VERSION ""

NS_ :

BS_:

BU_: TEST_NODE AREO_PRESSURE_SENS_B AREO_PRESSURE_SENS_A WHEEL_STRAIN_GAUGE_FR WHEEL_STRAIN_GAUGE_FL ACCU_FANS_DRIVER CAN_open_MASTER MAXON RES AREO_PRESSURE_SENS DV_BOARD RPI_LOGGER AREO_TEMP_SENS ANGLE_SENSOR BUZZER BRAKE_LIGHT MAIN SW LV_BMS Power_Module AMS_Master Pedals_frame GPS2CAN ADU FS_Datalogger
VAL_TABLE_ Rear_Sensor_Error 2 "OVER_RANGE" 1 "UNDER_RANGE" 0 "NO_ERROR" ;
VAL_TABLE_ Rear_CAN_Error 4 "CAN_FRAME_NOT_ACTUAL" 1 "NO_CAN_FRAME_READ" 0 "NO_ERROR" ;
VAL_TABLE_ Output_Error 2 "SET_ON_OVERCURRENT" 1 "OVERCURRENT" 0 "NO_ERROR" ;
VAL_TABLE_ BUZZER_REQUEST 2 "ASE" 1 "R2D" 0 "OFF" ;
VAL_TABLE_ Imd_Status_t 9 "IMD_STATE_UNKNOWN" 8 "IMD_STATE_INVALID_50HZ" 7 "IMD_STATE_KI31_FAULT_50HZ" 6 "IMD_STATE_INVALID_40HZ" 5 "IMD_STATE_DEVICE_ERROR_40HZ" 4 "IMD_STATE_INVALID_30HZ" 3 "IMD_STATE_SST_BAD_30HZ" 2 "IMD_STATE_SST_GOOD_30HZ" 1 "IMD_STATE_UNDERVOLT_20HZ" 0 "IMD_STATE_NORMAL_10HZ" ;
VAL_TABLE_ Main_State_t 5 "Error" 4 "TS_Shutdown" 3 "ReadyToDrive" 2 "TS_Active" 1 "Standby" 0 "Init" ;
VAL_TABLE_ SWAngleSensorTypeTable 5 "SENS_TLE5009_FIR" 4 "TLE5009_AVRG" 3 "MA734" 2 "MA730" 1 "AS5600" 0 "TLE5009" ;
VAL_TABLE_ BMS_State_t 9 "BMS_TIMEOUT" 8 "BMS_CELLS_BALANCING" 7 "BMS_BALANCING_TRANS" 6 "BMS_TSACTIVE_TRANS" 5 "BMS_ERROR" 4 "BMS_BP_BALANCING" 3 "BMS_TSACTIVE" 2 "BMS_PRECHARGE" 1 "BMS_TSOFF" 0 "BMS_INIT" ;
VAL_TABLE_ Service_brake_state_enum 3 "Service_brake_state_available" 2 "Service_brake_state_engaged" 1 "Service_brake_state_disengaged" ;
VAL_TABLE_ AMI_state_enum 6 "AMI_state_autocross" 5 "AMI_state_inspection" 4 "AMI_state_braketest" 3 "AMI_state_trackdrive" 2 "AMI_state_skidpad" 1 "AMI_state_acceleration" ;
VAL_TABLE_ EBS_state_enum 3 "EBS_state_activated" 2 "EBS_state_armed" 1 "EBS_state_unavailable" ;
VAL_TABLE_ AS_state_enum 5 "AS_state_finish" 4 "AS_state_emergency_brake" 3 "AS_state_driving " 2 "AS_state_ready" 1 "AS_state_off" ;

BO_ 3221225472 VECTOR__INDEPENDENT_SIG_MSG: 0 Vector__XXX
 SG_ AngleRLError : 0|8@0+ (1,0) [0|255] "" Vector__XXX
 SG_ AngleRL : 0|32@0- (1E-06,0) [-2147.483648|2147.483647] "deg" Vector__XXX
 SG_ AngleRRError : 0|8@0+ (1,0) [0|255] "" Vector__XXX
 SG_ AngleRR : 0|32@0- (1E-06,0) [-2147.483648|2147.483647] "deg" Vector__XXX
 SG_ AngleFLError : 0|8@0+ (1,0) [0|255] "" Vector__XXX
 SG_ AngleFL : 0|32@0- (1E-06,0) [-2147.483648|2147.483647] "deg" Vector__XXX
 SG_ AngleFRError : 0|8@0+ (1,0) [0|255] "" Vector__XXX
 SG_ AngleFR : 0|32@0- (1E-06,0) [-2147.483648|2147.483647] "deg" Vector__XXX
 SG_ AngleError : 0|8@0+ (1,0) [0|255] "" Vector__XXX
 SG_ Angle : 0|32@0- (1E-06,0) [-2147.483648|2147.483647] "deg" Vector__XXX
 SG_ AMKError : 0|8@0+ (1,0) [0|255] "" Vector__XXX
 SG_ AMS : 0|1@0+ (1,0) [0|255] "" Vector__XXX
 SG_ Buzzer : 0|8@0+ (1,0) [0|255] "" Vector__XXX

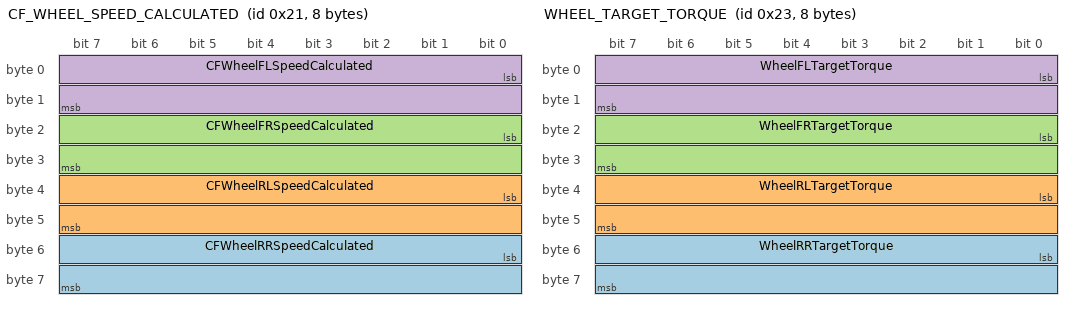
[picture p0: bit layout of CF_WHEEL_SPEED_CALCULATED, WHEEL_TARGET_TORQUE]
BO_ 33 CF_WHEEL_SPEED_CALCULATED: 8 MAIN
 SG_ CFWheelRRSpeedCalculated : 48|16@1- (1,0) [-32768|32767] "rpm"  RPI_LOGGER
 SG_ CFWheelRLSpeedCalculated : 32|16@1- (1,0) [-32768|32767] "rpm"  RPI_LOGGER
 SG_ CFWheelFRSpeedCalculated : 16|16@1- (1,0) [-32768|32767] "rpm"  RPI_LOGGER
 SG_ CFWheelFLSpeedCalculated : 0|16@1- (1,0) [-32768|32767] "rpm"  RPI_LOGGER

BO_ 35 WHEEL_TARGET_TORQUE: 8 MAIN
 SG_ WheelRRTargetTorque : 48|16@1- (1,0) [-32768|32767] "0.1% Mn"  RPI_LOGGER
 SG_ WheelRLTargetTorque : 32|16@1- (1,0) [-32768|32767] "0.1% Mn"  RPI_LOGGER
 SG_ WheelFRTargetTorque : 16|16@1- (1,0) [-32768|32767] "0.1% Mn"  RPI_LOGGER
 SG_ WheelFLTargetTorque : 0|16@1- (1,0) [-32768|32767] "0.1% Mn"  RPI_LOGGER

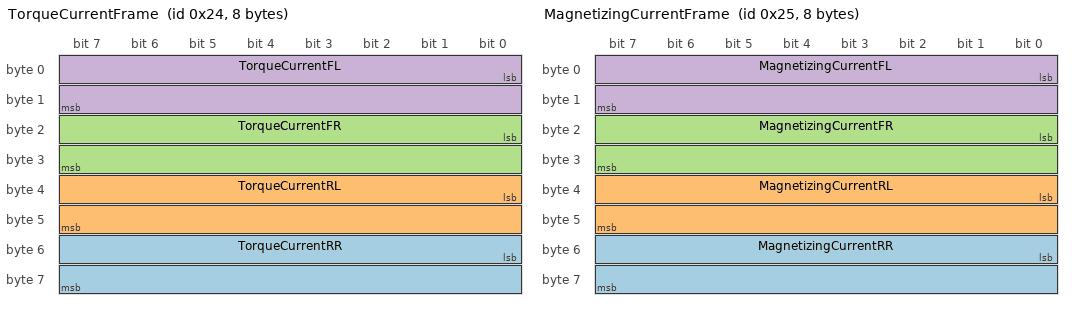
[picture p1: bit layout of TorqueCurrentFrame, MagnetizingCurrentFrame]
BO_ 36 TorqueCurrentFrame: 8 MAIN
 SG_ TorqueCurrentRR : 48|16@1- (1,0) [-32768|32767] "A"  RPI_LOGGER
 SG_ TorqueCurrentRL : 32|16@1- (1,0) [-32768|32767] "A"  RPI_LOGGER
 SG_ TorqueCurrentFR : 16|16@1- (1,0) [-32768|32767] "A"  RPI_LOGGER
 SG_ TorqueCurrentFL : 0|16@1- (1,0) [-32768|32767] "A"  RPI_LOGGER

BO_ 37 MagnetizingCurrentFrame: 8 MAIN
 SG_ MagnetizingCurrentRR : 48|16@1- (1,0) [-32768|32767] "A"  RPI_LOGGER
 SG_ MagnetizingCurrentRL : 32|16@1- (1,0) [-32768|32767] "A"  RPI_LOGGER
 SG_ MagnetizingCurrentFR : 16|16@1- (1,0) [-32768|32767] "A"  RPI_LOGGER
 SG_ MagnetizingCurrentFL : 0|16@1- (1,0) [-32768|32767] "A"  RPI_LOGGER

BO_ 1315 AMS_IMD_SDC_FRAME_DEBUG: 6 AMS_Master
 SG_ AMS_SDC_Volt_Debug : 24|16@1+ (0.001,0) [0|65.535] "V"  RPI_LOGGER
 SG_ ImdResistance : 8|16@1+ (1,0) [0|65535] "kOhm"  RPI_LOGGER
 SG_ ImdStatus : 0|8@1+ (1,0) [0|255] ""  RPI_LOGGER

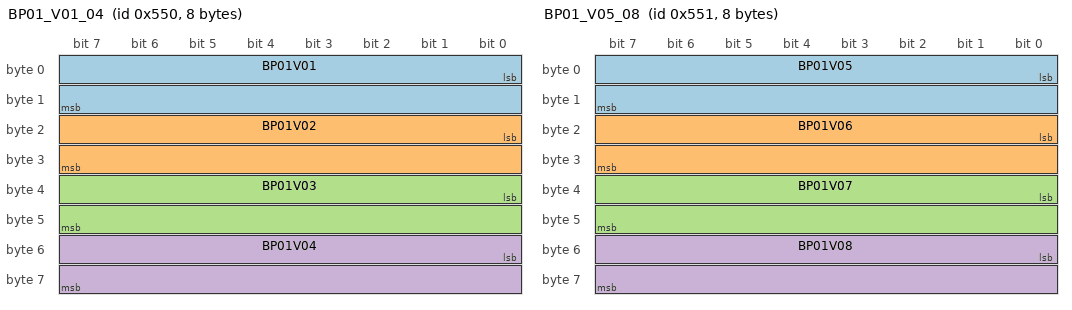
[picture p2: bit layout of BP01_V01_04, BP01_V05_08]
BO_ 1360 BP01_V01_04: 8 AMS_Master
 SG_ BP01V01 : 0|16@1+ (1,0) [0|65535] "mV"  RPI_LOGGER
 SG_ BP01V02 : 16|16@1+ (1,0) [0|65535] "mV"  RPI_LOGGER
 SG_ BP01V03 : 32|16@1+ (1,0) [0|65535] "mV"  RPI_LOGGER
 SG_ BP01V04 : 48|16@1+ (1,0) [0|65535] "mV"  RPI_LOGGER

BO_ 1361 BP01_V05_08: 8 AMS_Master
 SG_ BP01V05 : 0|16@1+ (1,0) [0|65535] "mV"  RPI_LOGGER
 SG_ BP01V06 : 16|16@1+ (1,0) [0|65535] "mV"  RPI_LOGGER
 SG_ BP01V07 : 32|16@1+ (1,0) [0|65535] "mV"  RPI_LOGGER
 SG_ BP01V08 : 48|16@1+ (1,0) [0|65535] "mV"  RPI_LOGGER

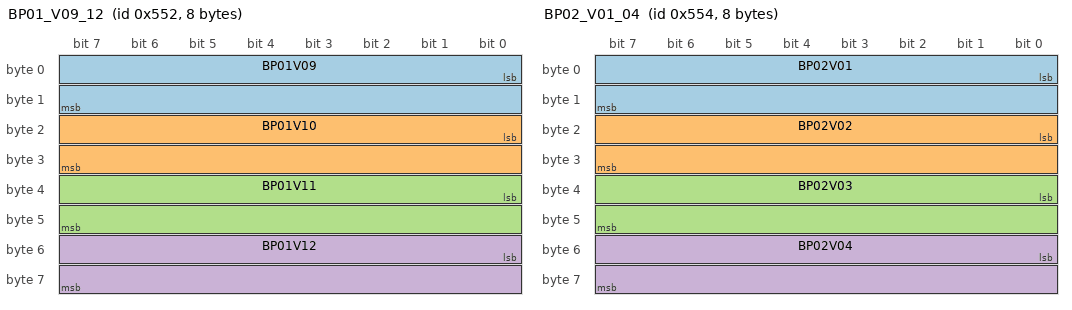
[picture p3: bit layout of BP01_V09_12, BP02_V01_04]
BO_ 1362 BP01_V09_12: 8 AMS_Master
 SG_ BP01V09 : 0|16@1+ (1,0) [0|65535] "mV"  RPI_LOGGER
 SG_ BP01V10 : 16|16@1+ (1,0) [0|65535] "mV"  RPI_LOGGER
 SG_ BP01V11 : 32|16@1+ (1,0) [0|65535] "mV"  RPI_LOGGER
 SG_ BP01V12 : 48|16@1+ (1,0) [0|65535] "mV"  RPI_LOGGER

BO_ 1363 BP01_V13_14: 8 AMS_Master
 SG_ BP01V13 : 0|16@1+ (1,0) [0|65535] "mV"  RPI_LOGGER
 SG_ BP01V14 : 16|16@1+ (1,0) [0|65535] "mV"  RPI_LOGGER

BO_ 1364 BP02_V01_04: 8 AMS_Master
 SG_ BP02V01 : 0|16@1+ (1,0) [0|65535] "mV"  RPI_LOGGER
 SG_ BP02V02 : 16|16@1+ (1,0) [0|65535] "mV"  RPI_LOGGER
 SG_ BP02V03 : 32|16@1+ (1,0) [0|65535] "mV"  RPI_LOGGER
 SG_ BP02V04 : 48|16@1+ (1,0) [0|65535] "mV"  RPI_LOGGER

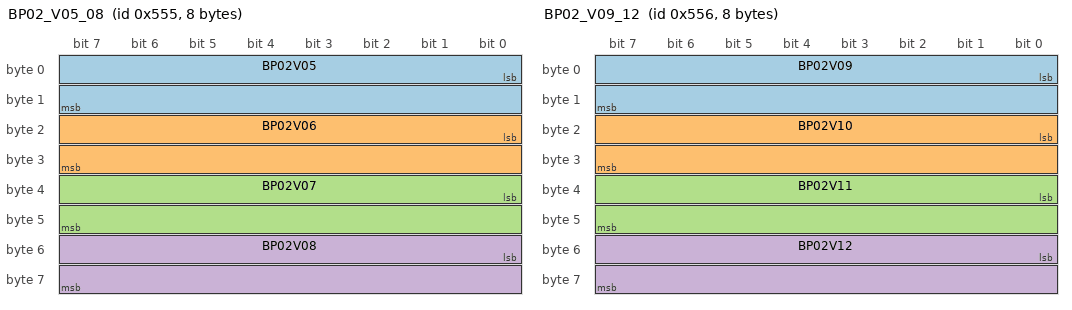
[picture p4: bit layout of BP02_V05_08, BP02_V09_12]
BO_ 1365 BP02_V05_08: 8 AMS_Master
 SG_ BP02V05 : 0|16@1+ (1,0) [0|65535] "mV"  RPI_LOGGER
 SG_ BP02V06 : 16|16@1+ (1,0) [0|65535] "mV"  RPI_LOGGER
 SG_ BP02V07 : 32|16@1+ (1,0) [0|65535] "mV"  RPI_LOGGER
 SG_ BP02V08 : 48|16@1+ (1,0) [0|65535] "mV"  RPI_LOGGER

BO_ 1366 BP02_V09_12: 8 AMS_Master
 SG_ BP02V09 : 0|16@1+ (1,0) [0|65535] "mV"  RPI_LOGGER
 SG_ BP02V10 : 16|16@1+ (1,0) [0|65535] "mV"  RPI_LOGGER
 SG_ BP02V11 : 32|16@1+ (1,0) [0|65535] "mV"  RPI_LOGGER
 SG_ BP02V12 : 48|16@1+ (1,0) [0|65535] "mV"  RPI_LOGGER

BO_ 1367 BP02_V13_14: 8 AMS_Master
 SG_ BP02V13 : 0|16@1+ (1,0) [0|65535] "mV"  RPI_LOGGER
 SG_ BP02V14 : 16|16@1+ (1,0) [0|65535] "mV"  RPI_LOGGER

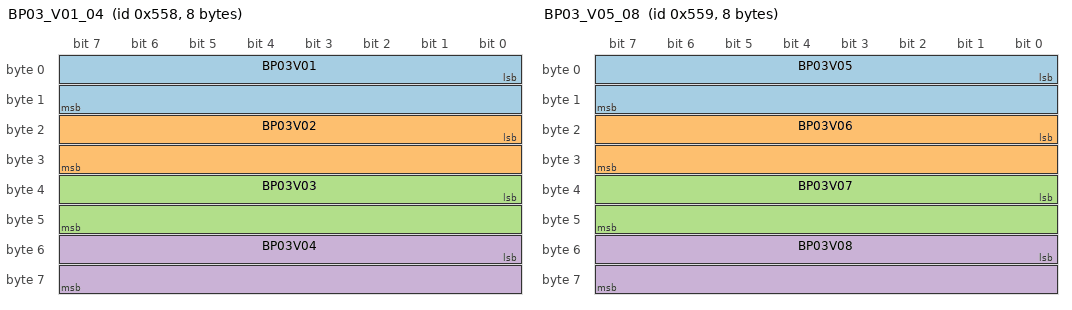
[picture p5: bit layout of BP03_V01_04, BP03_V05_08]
BO_ 1368 BP03_V01_04: 8 AMS_Master
 SG_ BP03V01 : 0|16@1+ (1,0) [0|65535] "mV"  RPI_LOGGER
 SG_ BP03V02 : 16|16@1+ (1,0) [0|65535] "mV"  RPI_LOGGER
 SG_ BP03V03 : 32|16@1+ (1,0) [0|65535] "mV"  RPI_LOGGER
 SG_ BP03V04 : 48|16@1+ (1,0) [0|65535] "mV"  RPI_LOGGER

BO_ 1369 BP03_V05_08: 8 AMS_Master
 SG_ BP03V05 : 0|16@1+ (1,0) [0|65535] "mV"  RPI_LOGGER
 SG_ BP03V06 : 16|16@1+ (1,0) [0|65535] "mV"  RPI_LOGGER
 SG_ BP03V07 : 32|16@1+ (1,0) [0|65535] "mV"  RPI_LOGGER
 SG_ BP03V08 : 48|16@1+ (1,0) [0|65535] "mV"  RPI_LOGGER

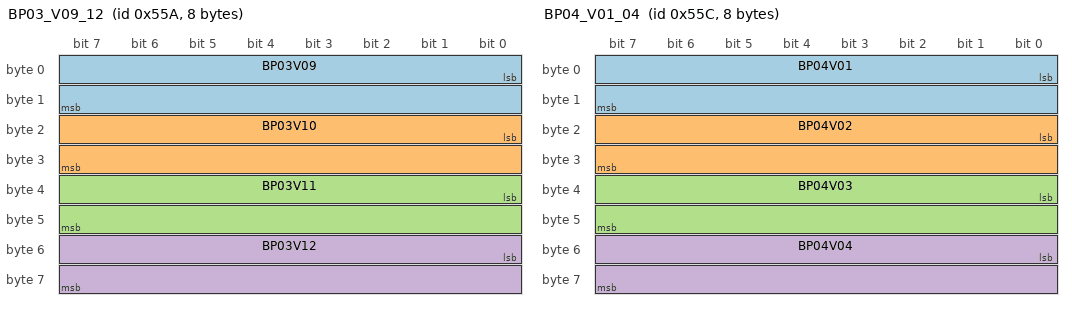
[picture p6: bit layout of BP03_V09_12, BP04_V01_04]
BO_ 1370 BP03_V09_12: 8 AMS_Master
 SG_ BP03V09 : 0|16@1+ (1,0) [0|65535] "mV"  RPI_LOGGER
 SG_ BP03V10 : 16|16@1+ (1,0) [0|65535] "mV"  RPI_LOGGER
 SG_ BP03V11 : 32|16@1+ (1,0) [0|65535] "mV"  RPI_LOGGER
 SG_ BP03V12 : 48|16@1+ (1,0) [0|65535] "mV"  RPI_LOGGER

BO_ 1371 BP03_V13_14: 8 AMS_Master
 SG_ BP03V13 : 0|16@1+ (1,0) [0|65535] "mV"  RPI_LOGGER
 SG_ BP03V14 : 16|16@1+ (1,0) [0|65535] "mV"  RPI_LOGGER

BO_ 1372 BP04_V01_04: 8 AMS_Master
 SG_ BP04V01 : 0|16@1+ (1,0) [0|65535] "mV"  RPI_LOGGER
 SG_ BP04V02 : 16|16@1+ (1,0) [0|65535] "mV"  RPI_LOGGER
 SG_ BP04V03 : 32|16@1+ (1,0) [0|65535] "mV"  RPI_LOGGER
 SG_ BP04V04 : 48|16@1+ (1,0) [0|65535] "mV"  RPI_LOGGER

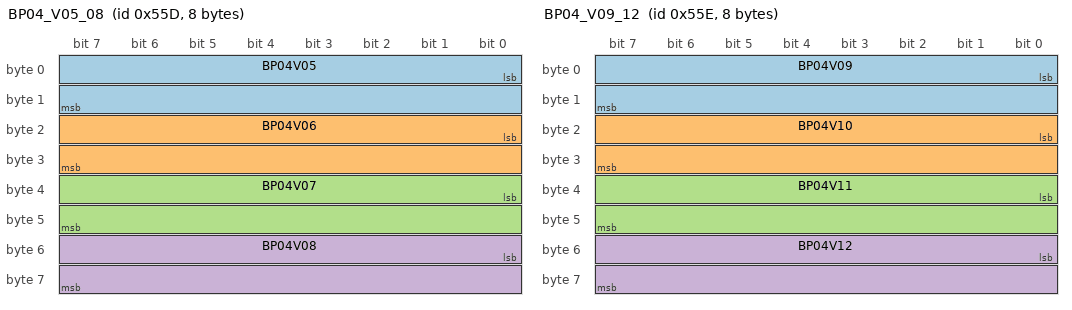
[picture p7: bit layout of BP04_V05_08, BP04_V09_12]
BO_ 1373 BP04_V05_08: 8 AMS_Master
 SG_ BP04V05 : 0|16@1+ (1,0) [0|65535] "mV"  RPI_LOGGER
 SG_ BP04V06 : 16|16@1+ (1,0) [0|65535] "mV"  RPI_LOGGER
 SG_ BP04V07 : 32|16@1+ (1,0) [0|65535] "mV"  RPI_LOGGER
 SG_ BP04V08 : 48|16@1+ (1,0) [0|65535] "mV"  RPI_LOGGER

BO_ 1374 BP04_V09_12: 8 AMS_Master
 SG_ BP04V09 : 0|16@1+ (1,0) [0|65535] "mV"  RPI_LOGGER
 SG_ BP04V10 : 16|16@1+ (1,0) [0|65535] "mV"  RPI_LOGGER
 SG_ BP04V11 : 32|16@1+ (1,0) [0|65535] "mV"  RPI_LOGGER
 SG_ BP04V12 : 48|16@1+ (1,0) [0|65535] "mV"  RPI_LOGGER

BO_ 1375 BP04_V13_14: 8 AMS_Master
 SG_ BP04V13 : 0|16@1+ (1,0) [0|65535] "mV"  RPI_LOGGER
 SG_ BP04V14 : 16|16@1+ (1,0) [0|65535] "mV"  RPI_LOGGER

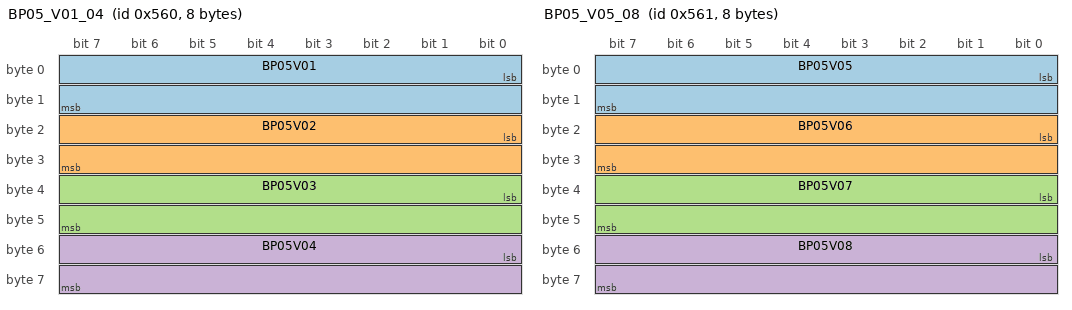
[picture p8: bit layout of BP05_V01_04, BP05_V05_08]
BO_ 1376 BP05_V01_04: 8 AMS_Master
 SG_ BP05V01 : 0|16@1+ (1,0) [0|65535] "mV"  RPI_LOGGER
 SG_ BP05V02 : 16|16@1+ (1,0) [0|65535] "mV"  RPI_LOGGER
 SG_ BP05V03 : 32|16@1+ (1,0) [0|65535] "mV"  RPI_LOGGER
 SG_ BP05V04 : 48|16@1+ (1,0) [0|65535] "mV"  RPI_LOGGER

BO_ 1377 BP05_V05_08: 8 AMS_Master
 SG_ BP05V05 : 0|16@1+ (1,0) [0|65535] "mV"  RPI_LOGGER
 SG_ BP05V06 : 16|16@1+ (1,0) [0|65535] "mV"  RPI_LOGGER
 SG_ BP05V07 : 32|16@1+ (1,0) [0|65535] "mV"  RPI_LOGGER
 SG_ BP05V08 : 48|16@1+ (1,0) [0|65535] "mV"  RPI_LOGGER

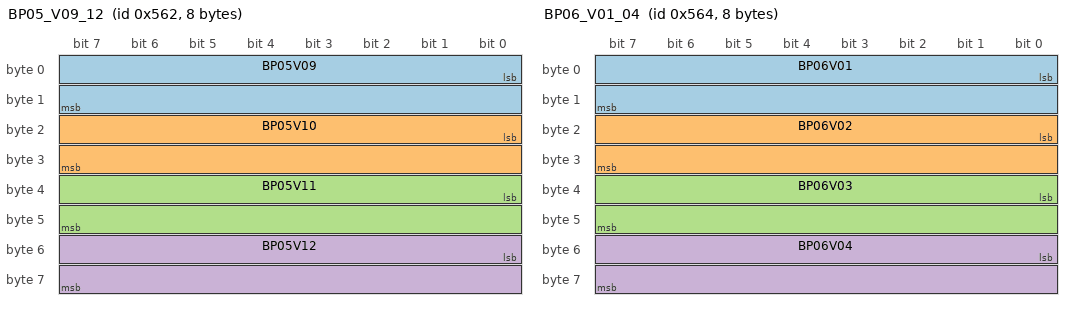
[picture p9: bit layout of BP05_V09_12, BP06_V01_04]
BO_ 1378 BP05_V09_12: 8 AMS_Master
 SG_ BP05V09 : 0|16@1+ (1,0) [0|65535] "mV"  RPI_LOGGER
 SG_ BP05V10 : 16|16@1+ (1,0) [0|65535] "mV"  RPI_LOGGER
 SG_ BP05V11 : 32|16@1+ (1,0) [0|65535] "mV"  RPI_LOGGER
 SG_ BP05V12 : 48|16@1+ (1,0) [0|65535] "mV"  RPI_LOGGER

BO_ 1379 BP05_V13_14: 8 AMS_Master
 SG_ BP05V13 : 0|16@1+ (1,0) [0|65535] "mV"  RPI_LOGGER
 SG_ BP05V14 : 16|16@1+ (1,0) [0|65535] "mV"  RPI_LOGGER

BO_ 1380 BP06_V01_04: 8 AMS_Master
 SG_ BP06V01 : 0|16@1+ (1,0) [0|65535] "mV"  RPI_LOGGER
 SG_ BP06V02 : 16|16@1+ (1,0) [0|65535] "mV"  RPI_LOGGER
 SG_ BP06V03 : 32|16@1+ (1,0) [0|65535] "mV"  RPI_LOGGER
 SG_ BP06V04 : 48|16@1+ (1,0) [0|65535] "mV"  RPI_LOGGER

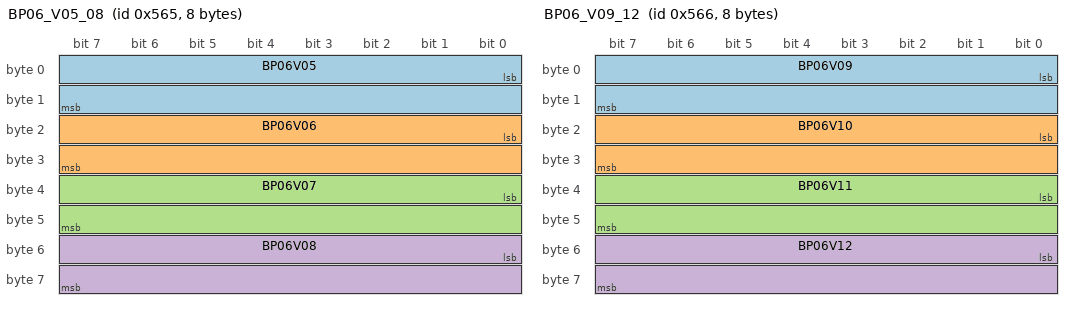
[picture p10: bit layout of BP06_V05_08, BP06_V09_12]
BO_ 1381 BP06_V05_08: 8 AMS_Master
 SG_ BP06V05 : 0|16@1+ (1,0) [0|65535] "mV"  RPI_LOGGER
 SG_ BP06V06 : 16|16@1+ (1,0) [0|65535] "mV"  RPI_LOGGER
 SG_ BP06V07 : 32|16@1+ (1,0) [0|65535] "mV"  RPI_LOGGER
 SG_ BP06V08 : 48|16@1+ (1,0) [0|65535] "mV"  RPI_LOGGER

BO_ 1382 BP06_V09_12: 8 AMS_Master
 SG_ BP06V09 : 0|16@1+ (1,0) [0|65535] "mV"  RPI_LOGGER
 SG_ BP06V10 : 16|16@1+ (1,0) [0|65535] "mV"  RPI_LOGGER
 SG_ BP06V11 : 32|16@1+ (1,0) [0|65535] "mV"  RPI_LOGGER
 SG_ BP06V12 : 48|16@1+ (1,0) [0|65535] "mV"  RPI_LOGGER

BO_ 1383 BP06_V13_14: 8 AMS_Master
 SG_ BP06V13 : 0|16@1+ (1,0) [0|65535] "mV"  RPI_LOGGER
 SG_ BP06V14 : 16|16@1+ (1,0) [0|65535] "mV"  RPI_LOGGER

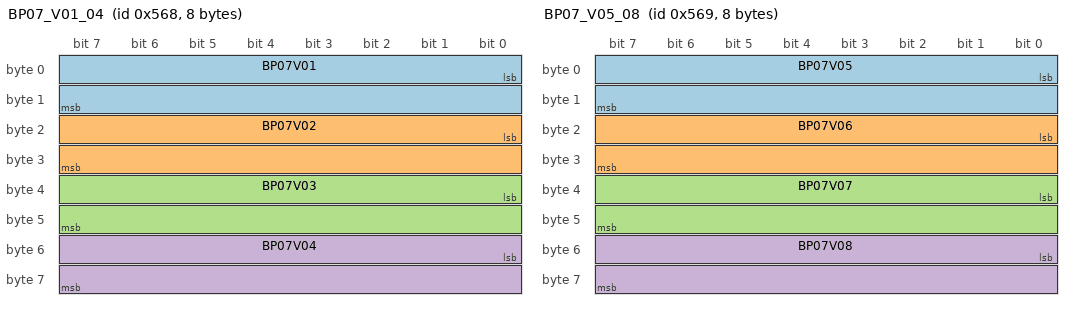
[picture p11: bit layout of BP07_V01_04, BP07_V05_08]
BO_ 1384 BP07_V01_04: 8 AMS_Master
 SG_ BP07V01 : 0|16@1+ (1,0) [0|65535] "mV"  RPI_LOGGER
 SG_ BP07V02 : 16|16@1+ (1,0) [0|65535] "mV"  RPI_LOGGER
 SG_ BP07V03 : 32|16@1+ (1,0) [0|65535] "mV"  RPI_LOGGER
 SG_ BP07V04 : 48|16@1+ (1,0) [0|65535] "mV"  RPI_LOGGER

BO_ 1385 BP07_V05_08: 8 AMS_Master
 SG_ BP07V05 : 0|16@1+ (1,0) [0|65535] "mV"  RPI_LOGGER
 SG_ BP07V06 : 16|16@1+ (1,0) [0|65535] "mV"  RPI_LOGGER
 SG_ BP07V07 : 32|16@1+ (1,0) [0|65535] "mV"  RPI_LOGGER
 SG_ BP07V08 : 48|16@1+ (1,0) [0|65535] "mV"  RPI_LOGGER

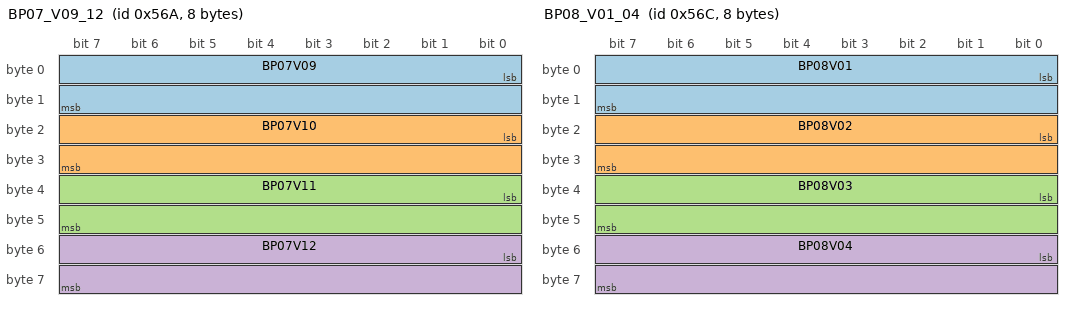
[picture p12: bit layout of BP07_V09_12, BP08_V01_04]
BO_ 1386 BP07_V09_12: 8 AMS_Master
 SG_ BP07V09 : 0|16@1+ (1,0) [0|65535] "mV"  RPI_LOGGER
 SG_ BP07V10 : 16|16@1+ (1,0) [0|65535] "mV"  RPI_LOGGER
 SG_ BP07V11 : 32|16@1+ (1,0) [0|65535] "mV"  RPI_LOGGER
 SG_ BP07V12 : 48|16@1+ (1,0) [0|65535] "mV"  RPI_LOGGER

BO_ 1387 BP07_V13_14: 8 AMS_Master
 SG_ BP07V13 : 0|16@1+ (1,0) [0|65535] "mV"  RPI_LOGGER
 SG_ BP07V14 : 16|16@1+ (1,0) [0|65535] "mV"  RPI_LOGGER

BO_ 1388 BP08_V01_04: 8 AMS_Master
 SG_ BP08V01 : 0|16@1+ (1,0) [0|65535] "mV"  RPI_LOGGER
 SG_ BP08V02 : 16|16@1+ (1,0) [0|65535] "mV"  RPI_LOGGER
 SG_ BP08V03 : 32|16@1+ (1,0) [0|65535] "mV"  RPI_LOGGER
 SG_ BP08V04 : 48|16@1+ (1,0) [0|65535] "mV"  RPI_LOGGER

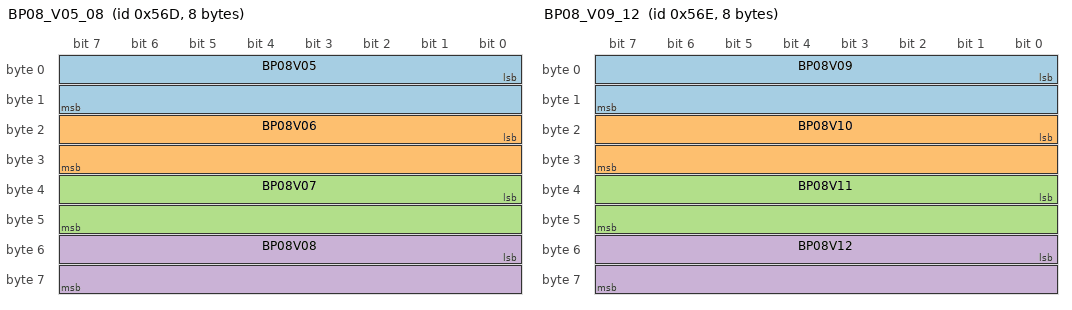
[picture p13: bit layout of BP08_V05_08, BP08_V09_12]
BO_ 1389 BP08_V05_08: 8 AMS_Master
 SG_ BP08V05 : 0|16@1+ (1,0) [0|65535] "mV"  RPI_LOGGER
 SG_ BP08V06 : 16|16@1+ (1,0) [0|65535] "mV"  RPI_LOGGER
 SG_ BP08V07 : 32|16@1+ (1,0) [0|65535] "mV"  RPI_LOGGER
 SG_ BP08V08 : 48|16@1+ (1,0) [0|65535] "mV"  RPI_LOGGER

BO_ 1390 BP08_V09_12: 8 AMS_Master
 SG_ BP08V09 : 0|16@1+ (1,0) [0|65535] "mV"  RPI_LOGGER
 SG_ BP08V10 : 16|16@1+ (1,0) [0|65535] "mV"  RPI_LOGGER
 SG_ BP08V11 : 32|16@1+ (1,0) [0|65535] "mV"  RPI_LOGGER
 SG_ BP08V12 : 48|16@1+ (1,0) [0|65535] "mV"  RPI_LOGGER

BO_ 1391 BP08_V13_14: 8 AMS_Master
 SG_ BP08V13 : 0|16@1+ (1,0) [0|65535] "mV"  RPI_LOGGER
 SG_ BP08V14 : 16|16@1+ (1,0) [0|65535] "mV"  RPI_LOGGER

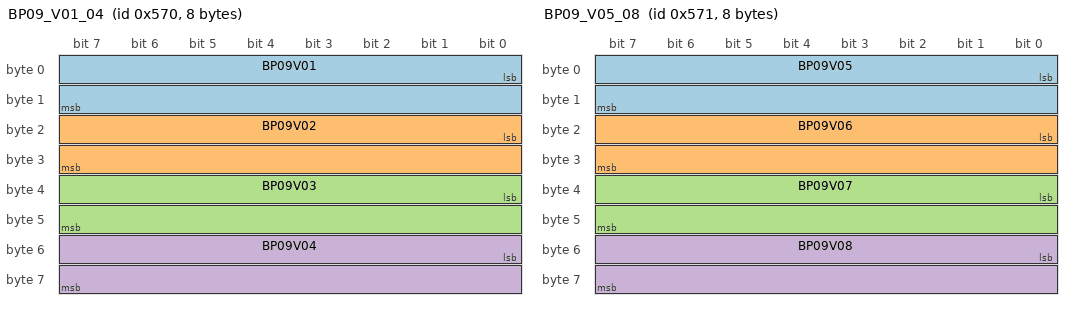
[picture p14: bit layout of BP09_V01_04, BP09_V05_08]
BO_ 1392 BP09_V01_04: 8 AMS_Master
 SG_ BP09V01 : 0|16@1+ (1,0) [0|65535] "mV"  RPI_LOGGER
 SG_ BP09V02 : 16|16@1+ (1,0) [0|65535] "mV"  RPI_LOGGER
 SG_ BP09V03 : 32|16@1+ (1,0) [0|65535] "mV"  RPI_LOGGER
 SG_ BP09V04 : 48|16@1+ (1,0) [0|65535] "mV"  RPI_LOGGER

BO_ 1393 BP09_V05_08: 8 AMS_Master
 SG_ BP09V05 : 0|16@1+ (1,0) [0|65535] "mV"  RPI_LOGGER
 SG_ BP09V06 : 16|16@1+ (1,0) [0|65535] "mV"  RPI_LOGGER
 SG_ BP09V07 : 32|16@1+ (1,0) [0|65535] "mV"  RPI_LOGGER
 SG_ BP09V08 : 48|16@1+ (1,0) [0|65535] "mV"  RPI_LOGGER

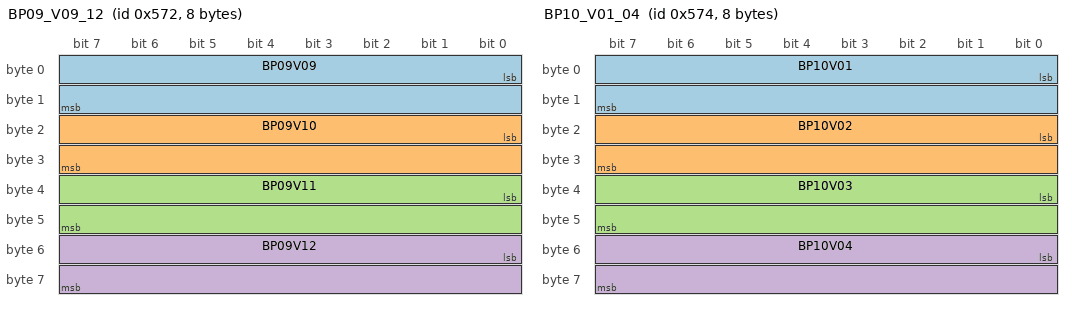
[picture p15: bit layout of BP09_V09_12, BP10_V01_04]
BO_ 1394 BP09_V09_12: 8 AMS_Master
 SG_ BP09V09 : 0|16@1+ (1,0) [0|65535] "mV"  RPI_LOGGER
 SG_ BP09V10 : 16|16@1+ (1,0) [0|65535] "mV"  RPI_LOGGER
 SG_ BP09V11 : 32|16@1+ (1,0) [0|65535] "mV"  RPI_LOGGER
 SG_ BP09V12 : 48|16@1+ (1,0) [0|65535] "mV"  RPI_LOGGER

BO_ 1395 BP09_V13_14: 8 AMS_Master
 SG_ BP09V13 : 0|16@1+ (1,0) [0|65535] "mV"  RPI_LOGGER
 SG_ BP09V14 : 16|16@1+ (1,0) [0|65535] "mV"  RPI_LOGGER

BO_ 1396 BP10_V01_04: 8 AMS_Master
 SG_ BP10V01 : 0|16@1+ (1,0) [0|65535] "mV"  RPI_LOGGER
 SG_ BP10V02 : 16|16@1+ (1,0) [0|65535] "mV"  RPI_LOGGER
 SG_ BP10V03 : 32|16@1+ (1,0) [0|65535] "mV"  RPI_LOGGER
 SG_ BP10V04 : 48|16@1+ (1,0) [0|65535] "mV"  RPI_LOGGER

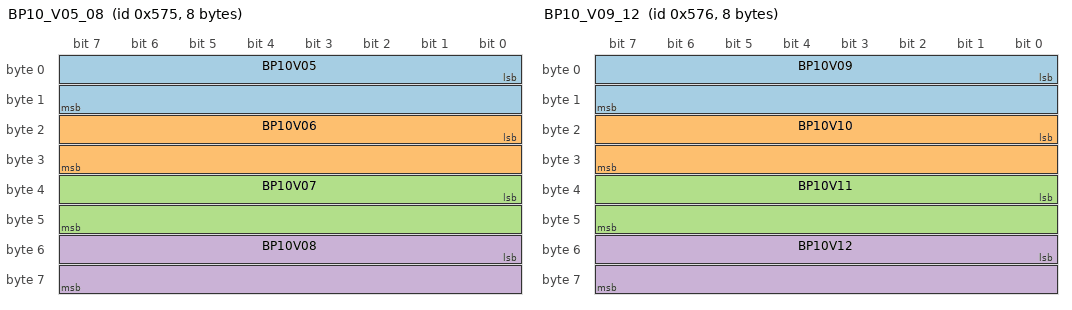
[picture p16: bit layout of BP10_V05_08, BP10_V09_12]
BO_ 1397 BP10_V05_08: 8 AMS_Master
 SG_ BP10V05 : 0|16@1+ (1,0) [0|65535] "mV"  RPI_LOGGER
 SG_ BP10V06 : 16|16@1+ (1,0) [0|65535] "mV"  RPI_LOGGER
 SG_ BP10V07 : 32|16@1+ (1,0) [0|65535] "mV"  RPI_LOGGER
 SG_ BP10V08 : 48|16@1+ (1,0) [0|65535] "mV"  RPI_LOGGER

BO_ 1398 BP10_V09_12: 8 AMS_Master
 SG_ BP10V09 : 0|16@1+ (1,0) [0|65535] "mV"  RPI_LOGGER
 SG_ BP10V10 : 16|16@1+ (1,0) [0|65535] "mV"  RPI_LOGGER
 SG_ BP10V11 : 32|16@1+ (1,0) [0|65535] "mV"  RPI_LOGGER
 SG_ BP10V12 : 48|16@1+ (1,0) [0|65535] "mV"  RPI_LOGGER

BO_ 1399 BP10_V13_14: 8 AMS_Master
 SG_ BP10V13 : 0|16@1+ (1,0) [0|65535] "mV"  RPI_LOGGER
 SG_ BP10V14 : 16|16@1+ (1,0) [0|65535] "mV"  RPI_LOGGER

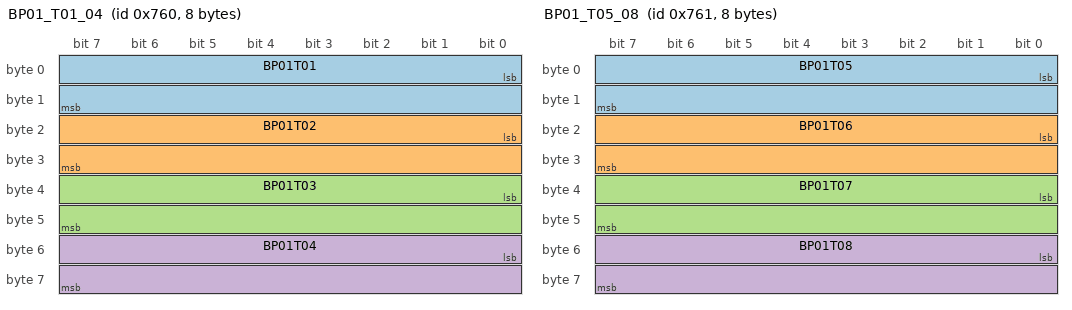
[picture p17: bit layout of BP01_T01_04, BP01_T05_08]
BO_ 1888 BP01_T01_04: 8 AMS_Master
 SG_ BP01T01 : 0|16@1+ (0.1,0) [0|6553.5] "C"  RPI_LOGGER
 SG_ BP01T02 : 16|16@1+ (0.1,0) [0|6553.5] "C"  RPI_LOGGER
 SG_ BP01T03 : 32|16@1+ (0.1,0) [0|6553.5] "C"  RPI_LOGGER
 SG_ BP01T04 : 48|16@1+ (0.1,0) [0|6553.5] "C"  RPI_LOGGER

BO_ 1889 BP01_T05_08: 8 AMS_Master
 SG_ BP01T05 : 0|16@1+ (0.1,0) [0|6553.5] "C"  RPI_LOGGER
 SG_ BP01T06 : 16|16@1+ (0.1,0) [0|6553.5] "C"  RPI_LOGGER
 SG_ BP01T07 : 32|16@1+ (0.1,0) [0|6553.5] "C"  RPI_LOGGER
 SG_ BP01T08 : 48|16@1+ (0.1,0) [0|6553.5] "C"  RPI_LOGGER

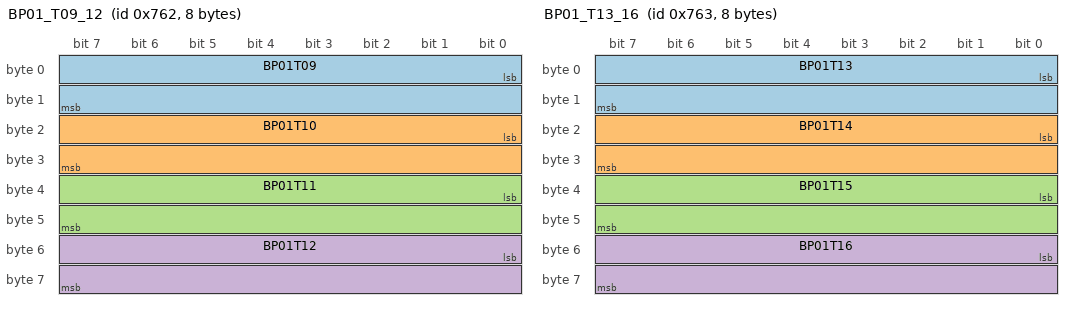
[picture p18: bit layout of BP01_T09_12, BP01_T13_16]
BO_ 1890 BP01_T09_12: 8 AMS_Master
 SG_ BP01T09 : 0|16@1+ (0.1,0) [0|6553.5] "C"  RPI_LOGGER
 SG_ BP01T10 : 16|16@1+ (0.1,0) [0|6553.5] "C"  RPI_LOGGER
 SG_ BP01T11 : 32|16@1+ (0.1,0) [0|6553.5] "C"  RPI_LOGGER
 SG_ BP01T12 : 48|16@1+ (0.1,0) [0|6553.5] "C"  RPI_LOGGER

BO_ 1891 BP01_T13_16: 8 AMS_Master
 SG_ BP01T13 : 0|16@1+ (0.1,0) [0|6553.5] "C"  RPI_LOGGER
 SG_ BP01T14 : 16|16@1+ (0.1,0) [0|6553.5] "C"  RPI_LOGGER
 SG_ BP01T15 : 32|16@1+ (0.1,0) [0|6553.5] "C"  RPI_LOGGER
 SG_ BP01T16 : 48|16@1+ (0.1,0) [0|6553.5] "C"  RPI_LOGGER

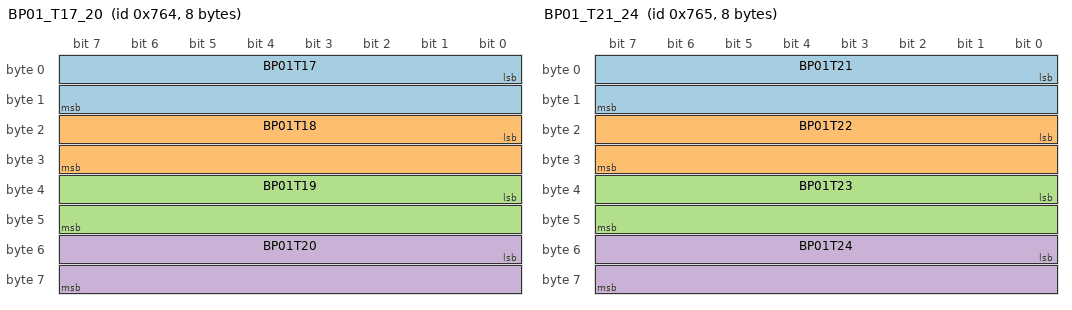
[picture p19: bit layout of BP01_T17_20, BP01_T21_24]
BO_ 1892 BP01_T17_20: 8 AMS_Master
 SG_ BP01T17 : 0|16@1+ (0.1,0) [0|6553.5] "C"  RPI_LOGGER
 SG_ BP01T18 : 16|16@1+ (0.1,0) [0|6553.5] "C"  RPI_LOGGER
 SG_ BP01T19 : 32|16@1+ (0.1,0) [0|6553.5] "C"  RPI_LOGGER
 SG_ BP01T20 : 48|16@1+ (0.1,0) [0|6553.5] "C"  RPI_LOGGER

BO_ 1893 BP01_T21_24: 8 AMS_Master
 SG_ BP01T21 : 0|16@1+ (0.1,0) [0|6553.5] "C"  RPI_LOGGER
 SG_ BP01T22 : 16|16@1+ (0.1,0) [0|6553.5] "C"  RPI_LOGGER
 SG_ BP01T23 : 32|16@1+ (0.1,0) [0|6553.5] "C"  RPI_LOGGER
 SG_ BP01T24 : 48|16@1+ (0.1,0) [0|6553.5] "C"  RPI_LOGGER

BO_ 1894 BP02_T01_04: 8 AMS_Master
 SG_ BP02T01 : 0|16@1+ (0.1,0) [0|6553.5] "C"  RPI_LOGGER
 SG_ BP02T02 : 16|16@1+ (0.1,0) [0|6553.5] "C"  RPI_LOGGER
 SG_ BP02T03 : 32|16@1+ (0.1,0) [0|6553.5] "C"  RPI_LOGGER
 SG_ BP02T04 : 48|16@1+ (0.1,0) [0|6553.5] "C"  RPI_LOGGER

BO_ 1895 BP02_T05_08: 8 AMS_Master
 SG_ BP02T05 : 0|16@1+ (0.1,0) [0|6553.5] "C"  RPI_LOGGER
 SG_ BP02T06 : 16|16@1+ (0.1,0) [0|6553.5] "C"  RPI_LOGGER
 SG_ BP02T07 : 32|16@1+ (0.1,0) [0|6553.5] "C"  RPI_LOGGER
 SG_ BP02T08 : 48|16@1+ (0.1,0) [0|6553.5] "C"  RPI_LOGGER

BO_ 1896 BP02_T09_12: 8 AMS_Master
 SG_ BP02T09 : 0|16@1+ (0.1,0) [0|6553.5] "C"  RPI_LOGGER
 SG_ BP02T10 : 16|16@1+ (0.1,0) [0|6553.5] "C"  RPI_LOGGER
 SG_ BP02T11 : 32|16@1+ (0.1,0) [0|6553.5] "C"  RPI_LOGGER
 SG_ BP02T12 : 48|16@1+ (0.1,0) [0|6553.5] "C"  RPI_LOGGER

BO_ 1897 BP02_T13_16: 8 AMS_Master
 SG_ BP02T13 : 0|16@1+ (0.1,0) [0|6553.5] "C"  RPI_LOGGER
 SG_ BP02T14 : 16|16@1+ (0.1,0) [0|6553.5] "C"  RPI_LOGGER
 SG_ BP02T15 : 32|16@1+ (0.1,0) [0|6553.5] "C"  RPI_LOGGER
 SG_ BP02T16 : 48|16@1+ (0.1,0) [0|6553.5] "C"  RPI_LOGGER

BO_ 1898 BP02_T17_20: 8 AMS_Master
 SG_ BP02T17 : 0|16@1+ (0.1,0) [0|6553.5] "C"  RPI_LOGGER
 SG_ BP02T18 : 16|16@1+ (0.1,0) [0|6553.5] "C"  RPI_LOGGER
 SG_ BP02T19 : 32|16@1+ (0.1,0) [0|6553.5] "C"  RPI_LOGGER
 SG_ BP02T20 : 48|16@1+ (0.1,0) [0|6553.5] "C"  RPI_LOGGER

BO_ 1899 BP02_T21_24: 8 AMS_Master
 SG_ BP02T21 : 0|16@1+ (0.1,0) [0|6553.5] "C"  RPI_LOGGER
 SG_ BP02T22 : 16|16@1+ (0.1,0) [0|6553.5] "C"  RPI_LOGGER
 SG_ BP02T23 : 32|16@1+ (0.1,0) [0|6553.5] "C"  RPI_LOGGER
 SG_ BP02T24 : 48|16@1+ (0.1,0) [0|6553.5] "C"  RPI_LOGGER

BO_ 1900 BP03_T01_04: 8 AMS_Master
 SG_ BP03T01 : 0|16@1+ (0.1,0) [0|6553.5] "C"  RPI_LOGGER
 SG_ BP03T02 : 16|16@1+ (0.1,0) [0|6553.5] "C"  RPI_LOGGER
 SG_ BP03T03 : 32|16@1+ (0.1,0) [0|6553.5] "C"  RPI_LOGGER
 SG_ BP03T04 : 48|16@1+ (0.1,0) [0|6553.5] "C"  RPI_LOGGER

BO_ 1901 BP03_T05_08: 8 AMS_Master
 SG_ BP03T05 : 0|16@1+ (0.1,0) [0|6553.5] "C"  RPI_LOGGER
 SG_ BP03T06 : 16|16@1+ (0.1,0) [0|6553.5] "C"  RPI_LOGGER
 SG_ BP03T07 : 32|16@1+ (0.1,0) [0|6553.5] "C"  RPI_LOGGER
 SG_ BP03T08 : 48|16@1+ (0.1,0) [0|6553.5] "C"  RPI_LOGGER

BO_ 1902 BP03_T09_12: 8 AMS_Master
 SG_ BP03T09 : 0|16@1+ (0.1,0) [0|6553.5] "C"  RPI_LOGGER
 SG_ BP03T10 : 16|16@1+ (0.1,0) [0|6553.5] "C"  RPI_LOGGER
 SG_ BP03T11 : 32|16@1+ (0.1,0) [0|6553.5] "C"  RPI_LOGGER
 SG_ BP03T12 : 48|16@1+ (0.1,0) [0|6553.5] "C"  RPI_LOGGER

BO_ 1903 BP03_T13_16: 8 AMS_Master
 SG_ BP03T13 : 0|16@1+ (0.1,0) [0|6553.5] "C"  RPI_LOGGER
 SG_ BP03T14 : 16|16@1+ (0.1,0) [0|6553.5] "C"  RPI_LOGGER
 SG_ BP03T15 : 32|16@1+ (0.1,0) [0|6553.5] "C"  RPI_LOGGER
 SG_ BP03T16 : 48|16@1+ (0.1,0) [0|6553.5] "C"  RPI_LOGGER

BO_ 1904 BP03_T17_20: 8 AMS_Master
 SG_ BP03T17 : 0|16@1+ (0.1,0) [0|6553.5] "C"  RPI_LOGGER
 SG_ BP03T18 : 16|16@1+ (0.1,0) [0|6553.5] "C"  RPI_LOGGER
 SG_ BP03T19 : 32|16@1+ (0.1,0) [0|6553.5] "C"  RPI_LOGGER
 SG_ BP03T20 : 48|16@1+ (0.1,0) [0|6553.5] "C"  RPI_LOGGER

BO_ 1905 BP03_T21_24: 8 AMS_Master
 SG_ BP03T21 : 0|16@1+ (0.1,0) [0|6553.5] "C"  RPI_LOGGER
 SG_ BP03T22 : 16|16@1+ (0.1,0) [0|6553.5] "C"  RPI_LOGGER
 SG_ BP03T23 : 32|16@1+ (0.1,0) [0|6553.5] "C"  RPI_LOGGER
 SG_ BP03T24 : 48|16@1+ (0.1,0) [0|6553.5] "C"  RPI_LOGGER

BO_ 1906 BP04_T01_04: 8 AMS_Master
 SG_ BP04T01 : 0|16@1+ (0.1,0) [0|6553.5] "C"  RPI_LOGGER
 SG_ BP04T02 : 16|16@1+ (0.1,0) [0|6553.5] "C"  RPI_LOGGER
 SG_ BP04T03 : 32|16@1+ (0.1,0) [0|6553.5] "C"  RPI_LOGGER
 SG_ BP04T04 : 48|16@1+ (0.1,0) [0|6553.5] "C"  RPI_LOGGER

BO_ 1907 BP04_T05_08: 8 AMS_Master
 SG_ BP04T05 : 0|16@1+ (0.1,0) [0|6553.5] "C"  RPI_LOGGER
 SG_ BP04T06 : 16|16@1+ (0.1,0) [0|6553.5] "C"  RPI_LOGGER
 SG_ BP04T07 : 32|16@1+ (0.1,0) [0|6553.5] "C"  RPI_LOGGER
 SG_ BP04T08 : 48|16@1+ (0.1,0) [0|6553.5] "C"  RPI_LOGGER

BO_ 1908 BP04_T09_12: 8 AMS_Master
 SG_ BP04T09 : 0|16@1+ (0.1,0) [0|6553.5] "C"  RPI_LOGGER
 SG_ BP04T10 : 16|16@1+ (0.1,0) [0|6553.5] "C"  RPI_LOGGER
 SG_ BP04T11 : 32|16@1+ (0.1,0) [0|6553.5] "C"  RPI_LOGGER
 SG_ BP04T12 : 48|16@1+ (0.1,0) [0|6553.5] "C"  RPI_LOGGER

BO_ 1909 BP04_T13_16: 8 AMS_Master
 SG_ BP04T13 : 0|16@1+ (0.1,0) [0|6553.5] "C"  RPI_LOGGER
 SG_ BP04T14 : 16|16@1+ (0.1,0) [0|6553.5] "C"  RPI_LOGGER
 SG_ BP04T15 : 32|16@1+ (0.1,0) [0|6553.5] "C"  RPI_LOGGER
 SG_ BP04T16 : 48|16@1+ (0.1,0) [0|6553.5] "C"  RPI_LOGGER

BO_ 1910 BP04_T17_20: 8 AMS_Master
 SG_ BP04T17 : 0|16@1+ (0.1,0) [0|6553.5] "C"  RPI_LOGGER
 SG_ BP04T18 : 16|16@1+ (0.1,0) [0|6553.5] "C"  RPI_LOGGER
 SG_ BP04T19 : 32|16@1+ (0.1,0) [0|6553.5] "C"  RPI_LOGGER
 SG_ BP04T20 : 48|16@1+ (0.1,0) [0|6553.5] "C"  RPI_LOGGER

BO_ 1911 BP04_T21_24: 8 AMS_Master
 SG_ BP04T21 : 0|16@1+ (0.1,0) [0|6553.5] "C"  RPI_LOGGER
 SG_ BP04T22 : 16|16@1+ (0.1,0) [0|6553.5] "C"  RPI_LOGGER
 SG_ BP04T23 : 32|16@1+ (0.1,0) [0|6553.5] "C"  RPI_LOGGER
 SG_ BP04T24 : 48|16@1+ (0.1,0) [0|6553.5] "C"  RPI_LOGGER

BO_ 1912 BP05_T01_04: 8 AMS_Master
 SG_ BP05T01 : 0|16@1+ (0.1,0) [0|6553.5] "C"  RPI_LOGGER
 SG_ BP05T02 : 16|16@1+ (0.1,0) [0|6553.5] "C"  RPI_LOGGER
 SG_ BP05T03 : 32|16@1+ (0.1,0) [0|6553.5] "C"  RPI_LOGGER
 SG_ BP05T04 : 48|16@1+ (0.1,0) [0|6553.5] "C"  RPI_LOGGER

BO_ 1913 BP05_T05_08: 8 AMS_Master
 SG_ BP05T05 : 0|16@1+ (0.1,0) [0|6553.5] "C"  RPI_LOGGER
 SG_ BP05T06 : 16|16@1+ (0.1,0) [0|6553.5] "C"  RPI_LOGGER
 SG_ BP05T07 : 32|16@1+ (0.1,0) [0|6553.5] "C"  RPI_LOGGER
 SG_ BP05T08 : 48|16@1+ (0.1,0) [0|6553.5] "C"  RPI_LOGGER

BO_ 1914 BP05_T09_12: 8 AMS_Master
 SG_ BP05T09 : 0|16@1+ (0.1,0) [0|6553.5] "C"  RPI_LOGGER
 SG_ BP05T10 : 16|16@1+ (0.1,0) [0|6553.5] "C"  RPI_LOGGER
 SG_ BP05T11 : 32|16@1+ (0.1,0) [0|6553.5] "C"  RPI_LOGGER
 SG_ BP05T12 : 48|16@1+ (0.1,0) [0|6553.5] "C"  RPI_LOGGER

BO_ 1915 BP05_T13_16: 8 AMS_Master
 SG_ BP05T13 : 0|16@1+ (0.1,0) [0|6553.5] "C"  RPI_LOGGER
 SG_ BP05T14 : 16|16@1+ (0.1,0) [0|6553.5] "C"  RPI_LOGGER
 SG_ BP05T15 : 32|16@1+ (0.1,0) [0|6553.5] "C"  RPI_LOGGER
 SG_ BP05T16 : 48|16@1+ (0.1,0) [0|6553.5] "C"  RPI_LOGGER

BO_ 1916 BP05_T17_20: 8 AMS_Master
 SG_ BP05T17 : 0|16@1+ (0.1,0) [0|6553.5] "C"  RPI_LOGGER
 SG_ BP05T18 : 16|16@1+ (0.1,0) [0|6553.5] "C"  RPI_LOGGER
 SG_ BP05T19 : 32|16@1+ (0.1,0) [0|6553.5] "C"  RPI_LOGGER
 SG_ BP05T20 : 48|16@1+ (0.1,0) [0|6553.5] "C"  RPI_LOGGER

BO_ 1917 BP05_T21_24: 8 AMS_Master
 SG_ BP05T21 : 0|16@1+ (0.1,0) [0|6553.5] "C"  RPI_LOGGER
 SG_ BP05T22 : 16|16@1+ (0.1,0) [0|6553.5] "C"  RPI_LOGGER
 SG_ BP05T23 : 32|16@1+ (0.1,0) [0|6553.5] "C"  RPI_LOGGER
 SG_ BP05T24 : 48|16@1+ (0.1,0) [0|6553.5] "C"  RPI_LOGGER

BO_ 1918 BP06_T01_04: 8 AMS_Master
 SG_ BP06T01 : 0|16@1+ (0.1,0) [0|6553.5] "C"  RPI_LOGGER
 SG_ BP06T02 : 16|16@1+ (0.1,0) [0|6553.5] "C"  RPI_LOGGER
 SG_ BP06T03 : 32|16@1+ (0.1,0) [0|6553.5] "C"  RPI_LOGGER
 SG_ BP06T04 : 48|16@1+ (0.1,0) [0|6553.5] "C"  RPI_LOGGER

BO_ 1919 BP06_T05_08: 8 AMS_Master
 SG_ BP06T05 : 0|16@1+ (0.1,0) [0|6553.5] "C"  RPI_LOGGER
 SG_ BP06T06 : 16|16@1+ (0.1,0) [0|6553.5] "C"  RPI_LOGGER
 SG_ BP06T07 : 32|16@1+ (0.1,0) [0|6553.5] "C"  RPI_LOGGER
 SG_ BP06T08 : 48|16@1+ (0.1,0) [0|6553.5] "C"  RPI_LOGGER

BO_ 1920 BP06_T09_12: 8 AMS_Master
 SG_ BP06T09 : 0|16@1+ (0.1,0) [0|6553.5] "C"  RPI_LOGGER
 SG_ BP06T10 : 16|16@1+ (0.1,0) [0|6553.5] "C"  RPI_LOGGER
 SG_ BP06T11 : 32|16@1+ (0.1,0) [0|6553.5] "C"  RPI_LOGGER
 SG_ BP06T12 : 48|16@1+ (0.1,0) [0|6553.5] "C"  RPI_LOGGER

BO_ 1921 BP06_T13_16: 8 AMS_Master
 SG_ BP06T13 : 0|16@1+ (0.1,0) [0|6553.5] "C"  RPI_LOGGER
 SG_ BP06T14 : 16|16@1+ (0.1,0) [0|6553.5] "C"  RPI_LOGGER
 SG_ BP06T15 : 32|16@1+ (0.1,0) [0|6553.5] "C"  RPI_LOGGER
 SG_ BP06T16 : 48|16@1+ (0.1,0) [0|6553.5] "C"  RPI_LOGGER

BO_ 1922 BP06_T17_20: 8 AMS_Master
 SG_ BP06T17 : 0|16@1+ (0.1,0) [0|6553.5] "C"  RPI_LOGGER
 SG_ BP06T18 : 16|16@1+ (0.1,0) [0|6553.5] "C"  RPI_LOGGER
 SG_ BP06T19 : 32|16@1+ (0.1,0) [0|6553.5] "C"  RPI_LOGGER
 SG_ BP06T20 : 48|16@1+ (0.1,0) [0|6553.5] "C"  RPI_LOGGER

BO_ 1923 BP06_T21_24: 8 AMS_Master
 SG_ BP06T21 : 0|16@1+ (0.1,0) [0|6553.5] "C"  RPI_LOGGER
 SG_ BP06T22 : 16|16@1+ (0.1,0) [0|6553.5] "C"  RPI_LOGGER
 SG_ BP06T23 : 32|16@1+ (0.1,0) [0|6553.5] "C"  RPI_LOGGER
 SG_ BP06T24 : 48|16@1+ (0.1,0) [0|6553.5] "C"  RPI_LOGGER

BO_ 1924 BP07_T01_04: 8 AMS_Master
 SG_ BP07T01 : 0|16@1+ (0.1,0) [0|6553.5] "C"  RPI_LOGGER
 SG_ BP07T02 : 16|16@1+ (0.1,0) [0|6553.5] "C"  RPI_LOGGER
 SG_ BP07T03 : 32|16@1+ (0.1,0) [0|6553.5] "C"  RPI_LOGGER
 SG_ BP07T04 : 48|16@1+ (0.1,0) [0|6553.5] "C"  RPI_LOGGER

BO_ 1925 BP07_T05_08: 8 AMS_Master
 SG_ BP07T05 : 0|16@1+ (0.1,0) [0|6553.5] "C"  RPI_LOGGER
 SG_ BP07T06 : 16|16@1+ (0.1,0) [0|6553.5] "C"  RPI_LOGGER
 SG_ BP07T07 : 32|16@1+ (0.1,0) [0|6553.5] "C"  RPI_LOGGER
 SG_ BP07T08 : 48|16@1+ (0.1,0) [0|6553.5] "C"  RPI_LOGGER

BO_ 1926 BP07_T09_12: 8 AMS_Master
 SG_ BP07T09 : 0|16@1+ (0.1,0) [0|6553.5] "C"  RPI_LOGGER
 SG_ BP07T10 : 16|16@1+ (0.1,0) [0|6553.5] "C"  RPI_LOGGER
 SG_ BP07T11 : 32|16@1+ (0.1,0) [0|6553.5] "C"  RPI_LOGGER
 SG_ BP07T12 : 48|16@1+ (0.1,0) [0|6553.5] "C"  RPI_LOGGER

BO_ 1927 BP07_T13_16: 8 AMS_Master
 SG_ BP07T13 : 0|16@1+ (0.1,0) [0|6553.5] "C"  RPI_LOGGER
 SG_ BP07T14 : 16|16@1+ (0.1,0) [0|6553.5] "C"  RPI_LOGGER
 SG_ BP07T15 : 32|16@1+ (0.1,0) [0|6553.5] "C"  RPI_LOGGER
 SG_ BP07T16 : 48|16@1+ (0.1,0) [0|6553.5] "C"  RPI_LOGGER

BO_ 1928 BP07_T17_20: 8 AMS_Master
 SG_ BP07T17 : 0|16@1+ (0.1,0) [0|6553.5] "C"  RPI_LOGGER
 SG_ BP07T18 : 16|16@1+ (0.1,0) [0|6553.5] "C"  RPI_LOGGER
 SG_ BP07T19 : 32|16@1+ (0.1,0) [0|6553.5] "C"  RPI_LOGGER
 SG_ BP07T20 : 48|16@1+ (0.1,0) [0|6553.5] "C"  RPI_LOGGER

BO_ 1929 BP07_T21_24: 8 AMS_Master
 SG_ BP07T21 : 0|16@1+ (0.1,0) [0|6553.5] "C"  RPI_LOGGER
 SG_ BP07T22 : 16|16@1+ (0.1,0) [0|6553.5] "C"  RPI_LOGGER
 SG_ BP07T23 : 32|16@1+ (0.1,0) [0|6553.5] "C"  RPI_LOGGER
 SG_ BP07T24 : 48|16@1+ (0.1,0) [0|6553.5] "C"  RPI_LOGGER

BO_ 1930 BP08_T01_04: 8 AMS_Master
 SG_ BP08T01 : 0|16@1+ (0.1,0) [0|6553.5] "C"  RPI_LOGGER
 SG_ BP08T02 : 16|16@1+ (0.1,0) [0|6553.5] "C"  RPI_LOGGER
 SG_ BP08T03 : 32|16@1+ (0.1,0) [0|6553.5] "C"  RPI_LOGGER
 SG_ BP08T04 : 48|16@1+ (0.1,0) [0|6553.5] "C"  RPI_LOGGER

BO_ 1931 BP08_T05_08: 8 AMS_Master
 SG_ BP08T05 : 0|16@1+ (0.1,0) [0|6553.5] "C"  RPI_LOGGER
 SG_ BP08T06 : 16|16@1+ (0.1,0) [0|6553.5] "C"  RPI_LOGGER
 SG_ BP08T07 : 32|16@1+ (0.1,0) [0|6553.5] "C"  RPI_LOGGER
 SG_ BP08T08 : 48|16@1+ (0.1,0) [0|6553.5] "C"  RPI_LOGGER

BO_ 1932 BP08_T09_12: 8 AMS_Master
 SG_ BP08T09 : 0|16@1+ (0.1,0) [0|6553.5] "C"  RPI_LOGGER
 SG_ BP08T10 : 16|16@1+ (0.1,0) [0|6553.5] "C"  RPI_LOGGER
 SG_ BP08T11 : 32|16@1+ (0.1,0) [0|6553.5] "C"  RPI_LOGGER
 SG_ BP08T12 : 48|16@1+ (0.1,0) [0|6553.5] "C"  RPI_LOGGER

BO_ 1933 BP08_T13_16: 8 AMS_Master
 SG_ BP08T13 : 0|16@1+ (0.1,0) [0|6553.5] "C"  RPI_LOGGER
 SG_ BP08T14 : 16|16@1+ (0.1,0) [0|6553.5] "C"  RPI_LOGGER
 SG_ BP08T15 : 32|16@1+ (0.1,0) [0|6553.5] "C"  RPI_LOGGER
 SG_ BP08T16 : 48|16@1+ (0.1,0) [0|6553.5] "C"  RPI_LOGGER

BO_ 1934 BP08_T17_20: 8 AMS_Master
 SG_ BP08T17 : 0|16@1+ (0.1,0) [0|6553.5] "C"  RPI_LOGGER
 SG_ BP08T18 : 16|16@1+ (0.1,0) [0|6553.5] "C"  RPI_LOGGER
 SG_ BP08T19 : 32|16@1+ (0.1,0) [0|6553.5] "C"  RPI_LOGGER
 SG_ BP08T20 : 48|16@1+ (0.1,0) [0|6553.5] "C"  RPI_LOGGER

BO_ 1935 BP08_T21_24: 8 AMS_Master
 SG_ BP08T21 : 0|16@1+ (0.1,0) [0|6553.5] "C"  RPI_LOGGER
 SG_ BP08T22 : 16|16@1+ (0.1,0) [0|6553.5] "C"  RPI_LOGGER
 SG_ BP08T23 : 32|16@1+ (0.1,0) [0|6553.5] "C"  RPI_LOGGER
 SG_ BP08T24 : 48|16@1+ (0.1,0) [0|6553.5] "C"  RPI_LOGGER

BO_ 1936 BP09_T01_04: 8 AMS_Master
 SG_ BP09T01 : 0|16@1+ (0.1,0) [0|6553.5] "C"  RPI_LOGGER
 SG_ BP09T02 : 16|16@1+ (0.1,0) [0|6553.5] "C"  RPI_LOGGER
 SG_ BP09T03 : 32|16@1+ (0.1,0) [0|6553.5] "C"  RPI_LOGGER
 SG_ BP09T04 : 48|16@1+ (0.1,0) [0|6553.5] "C"  RPI_LOGGER

BO_ 1937 BP09_T05_08: 8 AMS_Master
 SG_ BP09T05 : 0|16@1+ (0.1,0) [0|6553.5] "C"  RPI_LOGGER
 SG_ BP09T06 : 16|16@1+ (0.1,0) [0|6553.5] "C"  RPI_LOGGER
 SG_ BP09T07 : 32|16@1+ (0.1,0) [0|6553.5] "C"  RPI_LOGGER
 SG_ BP09T08 : 48|16@1+ (0.1,0) [0|6553.5] "C"  RPI_LOGGER

BO_ 1938 BP09_T09_12: 8 AMS_Master
 SG_ BP09T09 : 0|16@1+ (0.1,0) [0|6553.5] "C"  RPI_LOGGER
 SG_ BP09T10 : 16|16@1+ (0.1,0) [0|6553.5] "C"  RPI_LOGGER
 SG_ BP09T11 : 32|16@1+ (0.1,0) [0|6553.5] "C"  RPI_LOGGER
 SG_ BP09T12 : 48|16@1+ (0.1,0) [0|6553.5] "C"  RPI_LOGGER

BO_ 1939 BP09_T13_16: 8 AMS_Master
 SG_ BP09T13 : 0|16@1+ (0.1,0) [0|6553.5] "C"  RPI_LOGGER
 SG_ BP09T14 : 16|16@1+ (0.1,0) [0|6553.5] "C"  RPI_LOGGER
 SG_ BP09T15 : 32|16@1+ (0.1,0) [0|6553.5] "C"  RPI_LOGGER
 SG_ BP09T16 : 48|16@1+ (0.1,0) [0|6553.5] "C"  RPI_LOGGER

BO_ 1940 BP09_T17_20: 8 AMS_Master
 SG_ BP09T17 : 0|16@1+ (0.1,0) [0|6553.5] "C"  RPI_LOGGER
 SG_ BP09T18 : 16|16@1+ (0.1,0) [0|6553.5] "C"  RPI_LOGGER
 SG_ BP09T19 : 32|16@1+ (0.1,0) [0|6553.5] "C"  RPI_LOGGER
 SG_ BP09T20 : 48|16@1+ (0.1,0) [0|6553.5] "C"  RPI_LOGGER

BO_ 1941 BP09_T21_24: 8 AMS_Master
 SG_ BP09T21 : 0|16@1+ (0.1,0) [0|6553.5] "C"  RPI_LOGGER
 SG_ BP09T22 : 16|16@1+ (0.1,0) [0|6553.5] "C"  RPI_LOGGER
 SG_ BP09T23 : 32|16@1+ (0.1,0) [0|6553.5] "C"  RPI_LOGGER
 SG_ BP09T24 : 48|16@1+ (0.1,0) [0|6553.5] "C"  RPI_LOGGER

BO_ 1942 BP10_T01_04: 8 AMS_Master
 SG_ BP10T01 : 0|16@1+ (0.1,0) [0|6553.5] "C"  RPI_LOGGER
 SG_ BP10T02 : 16|16@1+ (0.1,0) [0|6553.5] "C"  RPI_LOGGER
 SG_ BP10T03 : 32|16@1+ (0.1,0) [0|6553.5] "C"  RPI_LOGGER
 SG_ BP10T04 : 48|16@1+ (0.1,0) [0|6553.5] "C"  RPI_LOGGER

BO_ 1943 BP10_T05_08: 8 AMS_Master
 SG_ BP10T05 : 0|16@1+ (0.1,0) [0|6553.5] "C"  RPI_LOGGER
 SG_ BP10T06 : 16|16@1+ (0.1,0) [0|6553.5] "C"  RPI_LOGGER
 SG_ BP10T07 : 32|16@1+ (0.1,0) [0|6553.5] "C"  RPI_LOGGER
 SG_ BP10T08 : 48|16@1+ (0.1,0) [0|6553.5] "C"  RPI_LOGGER

BO_ 1944 BP10_T09_12: 8 AMS_Master
 SG_ BP10T09 : 0|16@1+ (0.1,0) [0|6553.5] "C"  RPI_LOGGER
 SG_ BP10T10 : 16|16@1+ (0.1,0) [0|6553.5] "C"  RPI_LOGGER
 SG_ BP10T11 : 32|16@1+ (0.1,0) [0|6553.5] "C"  RPI_LOGGER
 SG_ BP10T12 : 48|16@1+ (0.1,0) [0|6553.5] "C"  RPI_LOGGER

BO_ 1945 BP10_T13_16: 8 AMS_Master
 SG_ BP10T13 : 0|16@1+ (0.1,0) [0|6553.5] "C"  RPI_LOGGER
 SG_ BP10T14 : 16|16@1+ (0.1,0) [0|6553.5] "C"  RPI_LOGGER
 SG_ BP10T15 : 32|16@1+ (0.1,0) [0|6553.5] "C"  RPI_LOGGER
 SG_ BP10T16 : 48|16@1+ (0.1,0) [0|6553.5] "C"  RPI_LOGGER

BO_ 1946 BP10_T17_20: 8 AMS_Master
 SG_ BP10T17 : 0|16@1+ (0.1,0) [0|6553.5] "C"  RPI_LOGGER
 SG_ BP10T18 : 16|16@1+ (0.1,0) [0|6553.5] "C"  RPI_LOGGER
 SG_ BP10T19 : 32|16@1+ (0.1,0) [0|6553.5] "C"  RPI_LOGGER
 SG_ BP10T20 : 48|16@1+ (0.1,0) [0|6553.5] "C"  RPI_LOGGER

BO_ 1947 BP10_T21_24: 8 AMS_Master
 SG_ BP10T21 : 0|16@1+ (0.1,0) [0|6553.5] "C"  RPI_LOGGER
 SG_ BP10T22 : 16|16@1+ (0.1,0) [0|6553.5] "C"  RPI_LOGGER
 SG_ BP10T23 : 32|16@1+ (0.1,0) [0|6553.5] "C"  RPI_LOGGER
 SG_ BP10T24 : 48|16@1+ (0.1,0) [0|6553.5] "C"  RPI_LOGGER

CM_ BO_ 3221225472 "This is a message for not used signals, created by Vector CANdb++ DBC OLE DB Provider.";
BA_DEF_ BO_  "Period" INT 0 10000;
BA_DEF_  "BusType" STRING ;
BA_DEF_DEF_  "Period" 100;
BA_DEF_DEF_  "BusType" "CAN";
BA_ "Period" BO_ 33 10;
BA_ "Period" BO_ 35 10;
BA_ "Period" BO_ 36 5;
BA_ "Period" BO_ 37 5;
BA_ "Period" BO_ 1315 1;
